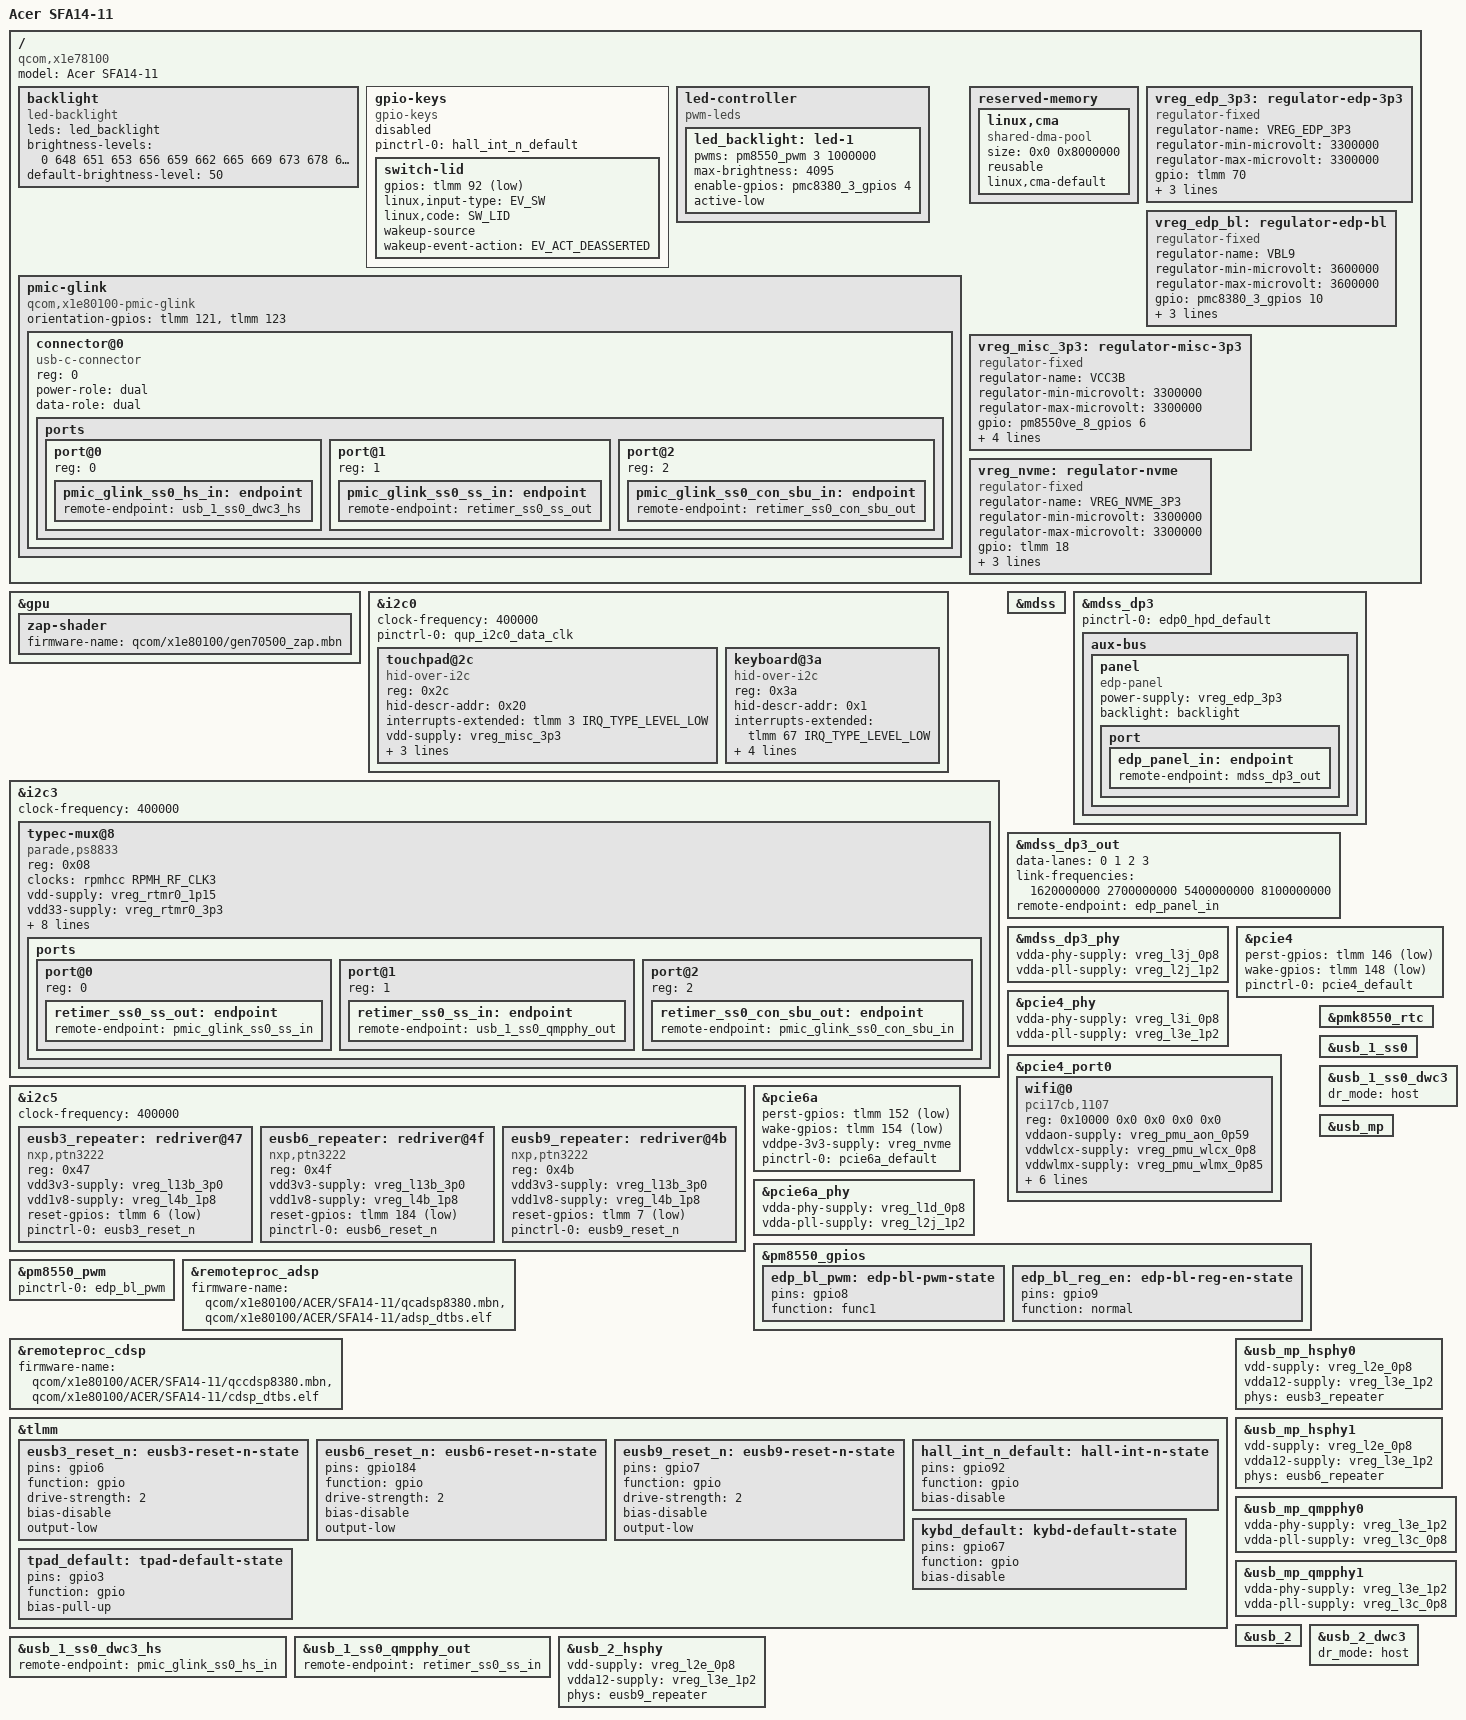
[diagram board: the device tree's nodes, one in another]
// SPDX-License-Identifier: BSD-3-Clause
/*
 * Copyright (c) 2023, Qualcomm Innovation Center, Inc. All rights reserved.
 * Copyright (c) 2025, Linaro Limited
 * Copyright (c) 2025, Zimo Zhang
 */

/dts-v1/;

#include "x1e78100-acer-sfa14-11.dtsi"
#include <dt-bindings/input/gpio-keys.h>

/ {
	model = "Acer SFA14-11";
	compatible = "qcom,x1e78100", "qcom,x1e80100", "lenovo,thinkpad-t14s";

	backlight: backlight {
		compatible = "led-backlight";

		leds = <&led_backlight>;
		brightness-levels = <0 648 651 653 656 659 662 665 669 673 678 683 689 695 702 709 717 725 734 744 754 764 776 787 800 813 827 841 856 872 889 906 923 942 961 981 1002 1023 1045 1068 1091 1116 1141 1167 1193 1221 1249 1278 1308 1338 1370 1402 1435 1469 1504 1539 1576 1613 1651 1690 1730 1771 1812 1855 1898 1942 1988 2034 2081 2129 2177 2227 2278 2329 2382 2436 2490 2546 2602 2659 2718 2777 2837 2898 2961 3024 3088 3154 3220 3287 3355 3425 3495 3566 3639 3712 3787 3862 3939 4016 4095>;
		default-brightness-level = <50>;
	};

	gpio-keys {
		compatible = "gpio-keys";

		pinctrl-0 = <&hall_int_n_default>;
		pinctrl-names = "default";

		status = "disabled"; // Disable before suspend is fixed

		switch-lid {
			gpios = <&tlmm 92 GPIO_ACTIVE_LOW>;
			linux,input-type = <EV_SW>;
			linux,code = <SW_LID>;
			wakeup-source;
			wakeup-event-action = <EV_ACT_DEASSERTED>;
		};
	};

	led-controller {
		compatible = "pwm-leds";

		led_backlight: led-1 {
			pwms = <&pm8550_pwm 3 1000000>; // 1kHz
			max-brightness = <4095>;

			enable-gpios = <&pmc8380_3_gpios 4 GPIO_ACTIVE_HIGH>;

			active-low; // Workaround: Qualcomm PMIC doesn't support PWM_POLARITY_INVERTED
		};
	};

	pmic-glink {
		compatible = "qcom,x1e80100-pmic-glink",
			     "qcom,sm8550-pmic-glink",
			     "qcom,pmic-glink";
		#address-cells = <1>;
		#size-cells = <0>;
		orientation-gpios = <&tlmm 121 GPIO_ACTIVE_HIGH>,
				    <&tlmm 123 GPIO_ACTIVE_HIGH>;

		connector@0 {
			compatible = "usb-c-connector";
			reg = <0>;
			power-role = "dual";
			data-role = "dual";

			ports {
				#address-cells = <1>;
				#size-cells = <0>;

				port@0 {
					reg = <0>;

					pmic_glink_ss0_hs_in: endpoint {
						remote-endpoint = <&usb_1_ss0_dwc3_hs>;
					};
				};

				port@1 {
					reg = <1>;

					pmic_glink_ss0_ss_in: endpoint {
						remote-endpoint = <&retimer_ss0_ss_out>;
					};
				};

				port@2 {
					reg = <2>;

					pmic_glink_ss0_con_sbu_in: endpoint {
						remote-endpoint = <&retimer_ss0_con_sbu_out>;
					};
				};
			};
		};
	};

	reserved-memory {
		linux,cma {
			compatible = "shared-dma-pool";
			size = <0x0 0x8000000>;
			reusable;
			linux,cma-default;
		};
	};

	vreg_edp_3p3: regulator-edp-3p3 {
		compatible = "regulator-fixed";

		regulator-name = "VREG_EDP_3P3";
		regulator-min-microvolt = <3300000>;
		regulator-max-microvolt = <3300000>;

		gpio = <&tlmm 70 GPIO_ACTIVE_HIGH>;
		enable-active-high;

		pinctrl-0 = <&edp_reg_en>;
		pinctrl-names = "default";

		regulator-boot-on;
	};

	vreg_edp_bl: regulator-edp-bl {
		compatible = "regulator-fixed";

		regulator-name = "VBL9";
		regulator-min-microvolt = <3600000>;
		regulator-max-microvolt = <3600000>;

		gpio = <&pmc8380_3_gpios 10 GPIO_ACTIVE_HIGH>;
		enable-active-high;

		pinctrl-0 = <&edp_bl_reg_en>;
		pinctrl-names = "default";

		regulator-boot-on;
	};

	vreg_misc_3p3: regulator-misc-3p3 {
		compatible = "regulator-fixed";

		regulator-name = "VCC3B";
		regulator-min-microvolt = <3300000>;
		regulator-max-microvolt = <3300000>;

		gpio = <&pm8550ve_8_gpios 6 GPIO_ACTIVE_HIGH>;
		enable-active-high;

		pinctrl-0 = <&misc_3p3_reg_en>;
		pinctrl-names = "default";

		regulator-boot-on;
		regulator-always-on;
	};

	vreg_nvme: regulator-nvme {
		compatible = "regulator-fixed";

		regulator-name = "VREG_NVME_3P3";
		regulator-min-microvolt = <3300000>;
		regulator-max-microvolt = <3300000>;

		gpio = <&tlmm 18 GPIO_ACTIVE_HIGH>;
		enable-active-high;

		pinctrl-names = "default";
		pinctrl-0 = <&nvme_reg_en>;

		regulator-boot-on;
	};
};

&gpu {
	status = "okay";

	zap-shader {
		firmware-name = "qcom/x1e80100/gen70500_zap.mbn";
	};
};

// Keyboard and Touchpad
&i2c0 {
	clock-frequency = <400000>;

	pinctrl-0 = <&qup_i2c0_data_clk>;
	pinctrl-names = "default";

	status = "okay";

	touchpad@2c {
		compatible = "hid-over-i2c";
		reg = <0x2c>;

		hid-descr-addr = <0x20>;
		interrupts-extended = <&tlmm 3 IRQ_TYPE_LEVEL_LOW>;

		vdd-supply = <&vreg_misc_3p3>;
		vddl-supply = <&vreg_l12b_1p2>;

		pinctrl-0 = <&tpad_default>;
		pinctrl-names = "default";

		wakeup-source;
	};

	keyboard@3a {
		compatible = "hid-over-i2c";
		reg = <0x3a>;

		hid-descr-addr = <0x1>;
		interrupts-extended = <&tlmm 67 IRQ_TYPE_LEVEL_LOW>;

		vdd-supply = <&vreg_misc_3p3>;
		vddl-supply = <&vreg_l15b_1p8>;

		pinctrl-0 = <&kybd_default>;
		pinctrl-names = "default";

		wakeup-source;
	};
};

&i2c3 {
	clock-frequency = <400000>;

	status = "okay";

	// USB-C
	typec-mux@8 {
		compatible = "parade,ps8833", "parade,ps8830";
		reg = <0x08>;

		clocks = <&rpmhcc RPMH_RF_CLK3>;

		vdd-supply = <&vreg_rtmr0_1p15>;
		vdd33-supply = <&vreg_rtmr0_3p3>;
		vdd33-cap-supply = <&vreg_rtmr0_3p3>;
		vddar-supply = <&vreg_rtmr0_1p15>;
		vddat-supply = <&vreg_rtmr0_1p15>;
		vddio-supply = <&vreg_rtmr0_1p8>;

		reset-gpios = <&pm8550_gpios 10 GPIO_ACTIVE_LOW>;

		pinctrl-0 = <&rtmr0_default>;
		pinctrl-names = "default";

		retimer-switch;
		orientation-switch;

		ports {
			#address-cells = <1>;
			#size-cells = <0>;

			port@0 {
				reg = <0>;

				retimer_ss0_ss_out: endpoint {
					remote-endpoint = <&pmic_glink_ss0_ss_in>;
				};
			};

			port@1 {
				reg = <1>;

				retimer_ss0_ss_in: endpoint {
					remote-endpoint = <&usb_1_ss0_qmpphy_out>;
				};
			};

			port@2 {
				reg = <2>;

				retimer_ss0_con_sbu_out: endpoint {
					remote-endpoint = <&pmic_glink_ss0_con_sbu_in>;
				};
			};
		};
	};
};

// Did not found NXP chips on board, found ps8719e instead, somehow PTN3222 probed successfully
&i2c5 {
	clock-frequency = <400000>;

	status = "okay";

	eusb3_repeater: redriver@47 {
		compatible = "nxp,ptn3222";
		reg = <0x47>;
		#phy-cells = <0>;

		vdd3v3-supply = <&vreg_l13b_3p0>;
		vdd1v8-supply = <&vreg_l4b_1p8>;

		reset-gpios = <&tlmm 6 GPIO_ACTIVE_LOW>;

		pinctrl-0 = <&eusb3_reset_n>;
		pinctrl-names = "default";
	};

	eusb6_repeater: redriver@4f {
		compatible = "nxp,ptn3222";
		reg = <0x4f>;
		#phy-cells = <0>;

		vdd3v3-supply = <&vreg_l13b_3p0>;
		vdd1v8-supply = <&vreg_l4b_1p8>;

		reset-gpios = <&tlmm 184 GPIO_ACTIVE_LOW>;

		pinctrl-0 = <&eusb6_reset_n>;
		pinctrl-names = "default";
	};

	eusb9_repeater: redriver@4b {
		compatible = "nxp,ptn3222";
		reg = <0x4b>;
		#phy-cells = <0>;

		vdd3v3-supply = <&vreg_l13b_3p0>;
		vdd1v8-supply = <&vreg_l4b_1p8>;

		reset-gpios = <&tlmm 7 GPIO_ACTIVE_LOW>;

		pinctrl-0 = <&eusb9_reset_n>;
		pinctrl-names = "default";
	};
};

&mdss {
	status = "okay";
};

// Integrated Display
&mdss_dp3 {
	/delete-property/ #sound-dai-cells;

	pinctrl-0 = <&edp0_hpd_default>;
	pinctrl-names = "default";

	status = "okay";

	aux-bus {
		panel: panel {
			compatible = "edp-panel";
			power-supply = <&vreg_edp_3p3>;

			port {
				edp_panel_in: endpoint {
					remote-endpoint = <&mdss_dp3_out>;
				};
			};
		};
	};
};

&mdss_dp3_out {
	data-lanes = <0 1 2 3>;
	link-frequencies = /bits/ 64 <1620000000 2700000000 5400000000 8100000000>;

	remote-endpoint = <&edp_panel_in>;
};

&mdss_dp3_phy {
	vdda-phy-supply = <&vreg_l3j_0p8>;
	vdda-pll-supply = <&vreg_l2j_1p2>;

	status = "okay";
};

&panel {
	backlight = <&backlight>;
};

// Wi-Fi
&pcie4 {
	perst-gpios = <&tlmm 146 GPIO_ACTIVE_LOW>;
	wake-gpios = <&tlmm 148 GPIO_ACTIVE_LOW>;

	pinctrl-0 = <&pcie4_default>;
	pinctrl-names = "default";

	status = "okay";
};

&pcie4_phy {
	vdda-phy-supply = <&vreg_l3i_0p8>;
	vdda-pll-supply = <&vreg_l3e_1p2>;

	status = "okay";
};

&pcie4_port0 {
	wifi@0 {
		compatible = "pci17cb,1107";
		reg = <0x10000 0x0 0x0 0x0 0x0>;

		vddaon-supply = <&vreg_pmu_aon_0p59>;
		vddwlcx-supply = <&vreg_pmu_wlcx_0p8>;
		vddwlmx-supply = <&vreg_pmu_wlmx_0p85>;
		vddrfacmn-supply = <&vreg_pmu_rfa_cmn>;
		vddrfa0p8-supply = <&vreg_pmu_rfa_0p8>;
		vddrfa1p2-supply = <&vreg_pmu_rfa_1p2>;
		vddrfa1p8-supply = <&vreg_pmu_rfa_1p8>;
		vddpcie0p9-supply = <&vreg_pmu_pcie_0p9>;
		vddpcie1p8-supply = <&vreg_pmu_pcie_1p8>;
	};
};

// NVMe Controller
&pcie6a {
	perst-gpios = <&tlmm 152 GPIO_ACTIVE_LOW>;
	wake-gpios = <&tlmm 154 GPIO_ACTIVE_LOW>;

	vddpe-3v3-supply = <&vreg_nvme>;

	pinctrl-names = "default";
	pinctrl-0 = <&pcie6a_default>;

	status = "okay";
};

&pcie6a_phy {
	vdda-phy-supply = <&vreg_l1d_0p8>;
	vdda-pll-supply = <&vreg_l2j_1p2>;

	status = "okay";
};

&pm8550_gpios {
	edp_bl_pwm: edp-bl-pwm-state {
		pins = "gpio8";
		function = "func1"; // Set PinMUX to PWM mode
	};

	edp_bl_reg_en: edp-bl-reg-en-state {
		pins = "gpio9";
		function = "normal";
	};
};

&pm8550_pwm {
	status = "okay";

	pinctrl-0 = <&edp_bl_pwm>;
	pinctrl-names = "default";
};

&pmk8550_rtc {
	/delete-property/ qcom,uefi-rtc-info; // Disable until QSEECOM is up
};

// Audio, battery indicator etc.
&remoteproc_adsp {
	firmware-name = "qcom/x1e80100/ACER/SFA14-11/qcadsp8380.mbn",
			"qcom/x1e80100/ACER/SFA14-11/adsp_dtbs.elf";

	status = "okay";
};

&remoteproc_cdsp {
	firmware-name = "qcom/x1e80100/ACER/SFA14-11/qccdsp8380.mbn",
			"qcom/x1e80100/ACER/SFA14-11/cdsp_dtbs.elf";

	status = "okay";
};

&tlmm {
	eusb3_reset_n: eusb3-reset-n-state {
		pins = "gpio6";
		function = "gpio";
		drive-strength = <2>;
		bias-disable;
		output-low;
	};

	eusb6_reset_n: eusb6-reset-n-state {
		pins = "gpio184";
		function = "gpio";
		drive-strength = <2>;
		bias-disable;
		output-low;
	};

	eusb9_reset_n: eusb9-reset-n-state {
		pins = "gpio7";
		function = "gpio";
		drive-strength = <2>;
		bias-disable;
		output-low;
	};

	hall_int_n_default: hall-int-n-state {
		pins = "gpio92";
		function = "gpio";
		bias-disable;
	};

	kybd_default: kybd-default-state {
		pins = "gpio67";
		function = "gpio";
		bias-disable;
	};

	tpad_default: tpad-default-state {
		pins = "gpio3";
		function = "gpio";
		bias-pull-up;
	};
};

// USB-C port
&usb_1_ss0 {
	status = "okay";
};

&usb_1_ss0_dwc3 {
	dr_mode = "host";
};

&usb_1_ss0_dwc3_hs {
	remote-endpoint = <&pmic_glink_ss0_hs_in>;
};

&usb_1_ss0_qmpphy_out {
	remote-endpoint = <&retimer_ss0_ss_in>;
};

// One of USB controller which connects most devices
&usb_mp {
	status = "okay";
};

// Not sure if all of these PHYs is available
&usb_mp_hsphy0 {
	vdd-supply = <&vreg_l2e_0p8>;
	vdda12-supply = <&vreg_l3e_1p2>;

	phys = <&eusb3_repeater>;

	status = "okay";
};

&usb_mp_hsphy1 {
	vdd-supply = <&vreg_l2e_0p8>;
	vdda12-supply = <&vreg_l3e_1p2>;

	phys = <&eusb6_repeater>;

	status = "okay";
};

&usb_mp_qmpphy0 {
	vdda-phy-supply = <&vreg_l3e_1p2>;
	vdda-pll-supply = <&vreg_l3c_0p8>;

	status = "okay";
};

&usb_mp_qmpphy1 {
	vdda-phy-supply = <&vreg_l3e_1p2>;
	vdda-pll-supply = <&vreg_l3c_0p8>;

	status = "okay";
};

// USB used by integrated UVC camera
&usb_2 {
	status = "okay";
};

&usb_2_dwc3 {
	dr_mode = "host";
};

&usb_2_hsphy {
	vdd-supply = <&vreg_l2e_0p8>;
	vdda12-supply = <&vreg_l3e_1p2>;

	phys = <&eusb9_repeater>;

	status = "okay";
};
